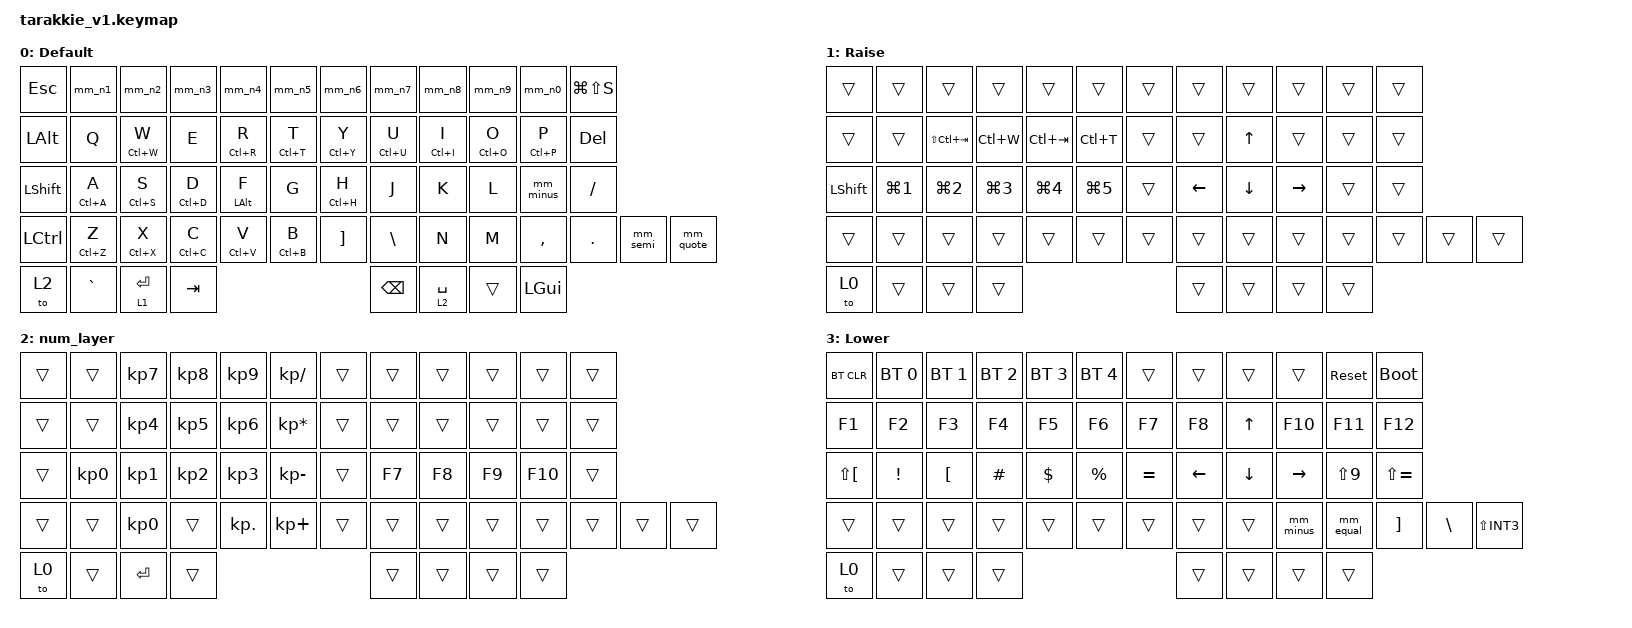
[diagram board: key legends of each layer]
/*
 * Copyright (c) 2025 The ZMK Contributors
 *
 * SPDX-License-Identifier: MIT
 */

#include <behaviors.dtsi>
#include <dt-bindings/zmk/bt.h>
#include <dt-bindings/zmk/keys.h>

// OS設定を日本語キーボードのまま使用するための変換定義

#define JP_DQUOTE       LS(N2)            // "
#define JP_AMPERSAND    LS(N6)            // &
#define JP_QUOTE        LS(N7)            // '
#define JP_EQUAL        LS(MINUS)         // =
#define JP_CARET        EQUAL             // ^
#define JP_YEN          INT3              // ¥
#define JP_PLUS         LS(SCLN)          // +
#define JP_TILDE        LS(EQUAL)         // ~
#define JP_PIPE         LS(INT3)          // |
#define JP_AT           LBKT              // @
#define JP_COLON        QUOT              // :
#define JP_ASTERISK     LS(QUOT)          // *
#define JP_BACKQUOTE    LS(LBKT)          // `
#define JP_UNDERSCORE   LS(INT1)          // _
#define JP_LBRACKET     RBKT              // [
#define JP_RBRACKET     BSLH              // ]
#define JP_LPAREN       LS(N8)            // (
#define JP_RPAREN       LS(N9)            // )
#define JP_LBRACE       LS(RBKT)          // {
#define JP_RBRACE       LS(BSLH)          // }

#define AS(keycode) &as LS(keycode) keycode

&mt {
    flavor = "tap-preferred";
};

/ {
    macros {
        tab_win: tab_win {
            compatible = "zmk,behavior-macro";
            #binding-cells = <0>;
            bindings = <&kp LG(TAB)>;
        };

        win_d: win_d {
            compatible = "zmk,behavior-macro";
            #binding-cells = <0>;
            bindings = <&kp LG(D)>;
        };

        l0_alt: l0_alt {
            compatible = "zmk,behavior-macro";
            #binding-cells = <0>;
            bindings =
                <&to 0>,
                <&macro_press>,
                <&kp LALT>,
                <&macro_pause_for_release>,
                <&macro_release>,
                <&kp LALT>;

            label = "L0_ALT";
        };

        l0_ctrl_a: l0_ctrl_a {
            compatible = "zmk,behavior-macro";
            #binding-cells = <0>;
            bindings = <&to 0 &kp LC(A)>;
            label = "L0_CTRL_A";
        };

        l0_ctrl_x: l0_ctrl_x {
            compatible = "zmk,behavior-macro";
            #binding-cells = <0>;
            bindings = <&to 0 &kp LC(X)>;
            label = "L0_CTRL_X";
        };

        l0_ctrl_c: l0_ctrl_c {
            compatible = "zmk,behavior-macro";
            #binding-cells = <0>;
            bindings = <&to 0 &kp LC(C)>;
            label = "L0_CTRL_C";
        };

        l0_ctrl_v: l0_ctrl_v {
            compatible = "zmk,behavior-macro";
            #binding-cells = <0>;
            bindings = <&to 0 &kp LC(V)>;
            label = "L0_CTRL_V";
        };
    };

    behaviors {
        ht_tab: ht_tab {
            compatible = "zmk,behavior-hold-tap";
            #binding-cells = <2>;
            flavor = "tap-preferred";
            tapping-term-ms = <200>;
            bindings = <&tab_win>, <&kp>;
        };

        ht_d: ht_d {
            compatible = "zmk,behavior-hold-tap";
            #binding-cells = <2>;
            flavor = "tap-preferred";
            tapping-term-ms = <200>;
            bindings = <&win_d>, <&kp>;
        };


        ht_g: ht_g {
            compatible = "zmk,behavior-hold-tap";
            #binding-cells = <2>;
            flavor = "tap-preferred";
            tapping-term-ms = <200>;
            bindings = <&to>, <&kp>;
        };

        ht_l0_alt: ht_l0_alt {
            compatible = "zmk,behavior-hold-tap";
            #binding-cells = <2>;
            flavor = "tap-preferred";
            tapping-term-ms = <200>;
            bindings = <&l0_alt>, <&kp>;
        };

        ht_l0_ctrl_a: ht_l0_ctrl_a {
            compatible = "zmk,behavior-hold-tap";
            #binding-cells = <2>;
            flavor = "tap-preferred";
            tapping-term-ms = <200>;
            bindings = <&l0_ctrl_a>, <&kp>;
        };

        ht_l0_ctrl_x: ht_l0_ctrl_x {
            compatible = "zmk,behavior-hold-tap";
            #binding-cells = <2>;
            flavor = "tap-preferred";
            tapping-term-ms = <200>;
            bindings = <&l0_ctrl_x>, <&kp>;
        };

        ht_l0_ctrl_c: ht_l0_ctrl_c {
            compatible = "zmk,behavior-hold-tap";
            #binding-cells = <2>;
            flavor = "tap-preferred";
            tapping-term-ms = <200>;
            bindings = <&l0_ctrl_c>, <&kp>;
        };

        ht_l0_ctrl_v: ht_l0_ctrl_v {
            compatible = "zmk,behavior-hold-tap";
            #binding-cells = <2>;
            flavor = "tap-preferred";
            tapping-term-ms = <200>;
            bindings = <&l0_ctrl_v>, <&kp>;
        };

        td_lang: td_lang {
            compatible = "zmk,behavior-tap-dance";
            #binding-cells = <0>;
            tapping-term-ms = <200>;
            bindings = <&kp LANGUAGE_1>, <&kp LANGUAGE_2>;
        };

        // US Keycap Emulation for JIS OS (Mod-Morph + Hold-Tap for Numbers)

        mm_n1: mm_n1 {
            compatible = "zmk,behavior-mod-morph";
            #binding-cells = <0>;
            bindings = <&mt F1 N1>, <&kp EXCLAMATION>;

            mods = <(MOD_LSFT|MOD_RSFT)>;
        };

        mm_n2: mm_n2 {
            compatible = "zmk,behavior-mod-morph";
            #binding-cells = <0>;
            bindings = <&mt F2 N2>, <&kp JP_AT>;

            mods = <(MOD_LSFT|MOD_RSFT)>;
        };

        mm_n3: mm_n3 {
            compatible = "zmk,behavior-mod-morph";
            #binding-cells = <0>;
            bindings = <&mt F3 N3>, <&kp HASH>;

            mods = <(MOD_LSFT|MOD_RSFT)>;
        };

        mm_n4: mm_n4 {
            compatible = "zmk,behavior-mod-morph";
            #binding-cells = <0>;
            bindings = <&mt F4 N4>, <&kp DOLLAR>;

            mods = <(MOD_LSFT|MOD_RSFT)>;
        };

        mm_n5: mm_n5 {
            compatible = "zmk,behavior-mod-morph";
            #binding-cells = <0>;
            bindings = <&mt F5 N5>, <&kp PERCENT>;

            mods = <(MOD_LSFT|MOD_RSFT)>;
        };

        mm_n6: mm_n6 {
            compatible = "zmk,behavior-mod-morph";
            #binding-cells = <0>;
            bindings = <&mt F6 N6>, <&kp JP_CARET>;

            mods = <(MOD_LSFT|MOD_RSFT)>;
        };

        mm_n7: mm_n7 {
            compatible = "zmk,behavior-mod-morph";
            #binding-cells = <0>;
            bindings = <&mt F7 N7>, <&kp JP_AMPERSAND>;

            mods = <(MOD_LSFT|MOD_RSFT)>;
        };

        mm_n8: mm_n8 {
            compatible = "zmk,behavior-mod-morph";
            #binding-cells = <0>;
            bindings = <&mt F8 N8>, <&kp JP_ASTERISK>;

            mods = <(MOD_LSFT|MOD_RSFT)>;
        };

        mm_n9: mm_n9 {
            compatible = "zmk,behavior-mod-morph";
            #binding-cells = <0>;
            bindings = <&mt F9 N9>, <&kp JP_LPAREN>;

            mods = <(MOD_LSFT|MOD_RSFT)>;
        };

        mm_n0: mm_n0 {
            compatible = "zmk,behavior-mod-morph";
            #binding-cells = <0>;
            bindings = <&mt F10 N0>, <&kp JP_RPAREN>;

            mods = <(MOD_LSFT|MOD_RSFT)>;
        };

        mm_semi: mm_semi {
            compatible = "zmk,behavior-mod-morph";
            #binding-cells = <0>;
            bindings = <&kp SEMI>, <&kp JP_COLON>;

            mods = <(MOD_LSFT|MOD_RSFT)>;
        };

        mm_quote: mm_quote {
            compatible = "zmk,behavior-mod-morph";
            #binding-cells = <0>;
            bindings = <&kp JP_QUOTE>, <&kp JP_DQUOTE>;

            mods = <(MOD_LSFT|MOD_RSFT)>;
        };

        mm_minus: mm_minus {
            compatible = "zmk,behavior-mod-morph";
            #binding-cells = <0>;
            bindings = <&kp MINUS>, <&kp JP_UNDERSCORE>;

            mods = <(MOD_LSFT|MOD_RSFT)>;
        };

        mm_equal: mm_equal {
            compatible = "zmk,behavior-mod-morph";
            #binding-cells = <0>;
            bindings = <&kp JP_EQUAL>, <&kp JP_PLUS>;

            mods = <(MOD_LSFT|MOD_RSFT)>;
        };
    };

    combos {
        compatible = "zmk,combos";

        win+d {
            bindings = <&kp LG(D)>;
            key-positions = <27 52>;
        };

        win+tab {
            bindings = <&kp LG(TAB)>;
            key-positions = <28 52>;
        };

        f2 {
            bindings = <&kp F2>;
            key-positions = <27 28>;
        };

        alt+f4 {
            bindings = <&kp LA(F4)>;
            key-positions = <27 28 52>;
        };

        lang1 {
            bindings = <&kp LANGUAGE_1>;
            key-positions = <28 31>;
        };

        lang2 {
            bindings = <&kp LANGUAGE_2>;
            key-positions = <27 32>;
        };

        paste {
            bindings = <&mt LG(V) LS(LC(V))>;
            key-positions = <52 40>;
        };

        combo_lparen {
            bindings = <&kp JP_LPAREN>;
            key-positions = <15 16>;
        };

        combo_rparen {
            bindings = <&kp JP_RPAREN>;
            key-positions = <19 20>;
        };
    };

    keymap {
        compatible = "zmk,keymap";

        default_layer {
            display-name = "Default";

            // ------------------------------------------------------------------------------------------------------------
            // |  ESC  |  1  |  2  |  3   |  4   |  5   |                   |  6   |  7    |  8    |  9   |   0   |   `   |
            // |  TAB  |  Q  |  W  |  E   |  R   |  T   |                   |  Y   |  U    |  I    |  O   |   P   |   -   |
            // |  CTRL |  A  |  S  | W+D  |  F   |  G   |                   |  H   |  J    |  K    |  L   |   ;   |   '   |
            // | SHIFT |  Z  |  X  |  C   |  V   |  B   |   "("  |  |  ")"  |  N   |  M    |  ,    |  .   |   ;   |   '   |
            //                     | ALT  | LANG | TAB |  ENTER |  | SPACE | BKSP  | BSPC  | GUI   |

            bindings = <
&kp ESC       &mm_n1         &mm_n2       &mm_n3       &mm_n4          &mm_n5       &mm_n6         &mm_n7         &mm_n8       &mm_n9       &mm_n0        &kp LG(LS(S))
&kp LEFT_ALT  &kp Q          &mt LC(W) W  &kp E        &mt LC(R) R     &mt LC(T) T  &mt LC(Y) Y    &mt LC(U) U    &mt LC(I) I  &mt LC(O) O  &mt LC(P) P   &kp DEL
&kp LSHIFT    &mt LC(A) A    &mt LC(S) S  &mt LC(D) D  &mt LEFT_ALT F  &kp G        &mt LC(H) H    &kp J          &kp K        &kp L        &mm_minus     &kp SLASH
&kp LCTRL     &mt LC(Z) Z    &mt LC(X) X  &mt LC(C) C  &mt LC(V) V     &mt LC(B) B  &kp JP_LBRACKET  &kp JP_RBRACKET  &kp N        &kp M        &kp COMMA     &kp DOT        &mm_semi  &mm_quote
&to 2         &kp GRAVE      &lt 1 ENTER  &kp TAB                                                  &kp BACKSPACE  &lt 2 SPACE  &trans       &kp LEFT_GUI
            >;
        };

        fn_layer {
            display-name = "Raise";
            bindings = <
&trans      &trans            &trans            &trans            &trans            &trans      &trans  &trans    &trans    &trans     &trans  &trans
&trans      &trans            &kp LS(LC(TAB))   &kp LC(W)         &kp LC(TAB)       &kp LC(T)   &trans  &trans    &kp UP    &trans     &trans  &trans
&kp LSHIFT  &kp LG(NUMBER_1)  &kp LG(NUMBER_2)  &kp LG(NUMBER_3)  &kp LG(NUMBER_4)  &kp LG(N5)  &trans  &kp LEFT  &kp DOWN  &kp RIGHT  &trans  &trans
&trans      &trans            &trans            &trans            &trans            &trans      &trans  &trans    &trans    &trans     &trans  &trans  &trans  &trans
&to 0       &trans            &trans            &trans                                                  &trans    &trans    &trans     &trans
            >;
        };

        num_layer {
            bindings = <
&trans  &trans           &kp KP_NUMBER_7  &kp KP_NUMBER_8  &kp KP_NUMBER_9  &kp KP_SLASH     &trans  &trans  &trans  &trans  &trans   &trans
&trans  &trans           &kp KP_NUMBER_4  &kp KP_NUMBER_5  &kp KP_NUMBER_6  &kp KP_MULTIPLY  &trans  &trans  &trans  &trans  &trans   &trans
&trans  &kp KP_NUMBER_0  &kp KP_NUMBER_1  &kp KP_NUMBER_2  &kp KP_NUMBER_3  &kp KP_MINUS     &trans  &kp F7  &kp F8  &kp F9  &kp F10  &trans
&trans  &trans           &kp KP_NUMBER_0  &trans           &kp KP_DOT       &kp KP_PLUS      &trans  &trans  &trans  &trans  &trans   &trans  &trans  &trans
&to 0   &trans           &kp ENTER        &trans                                                     &trans  &trans  &trans  &trans
            >;
        };

        setup_layer {
            display-name = "Lower";
            bindings = <
&bt BT_CLR        &bt BT_SEL 0  &bt BT_SEL 1  &bt BT_SEL 2  &bt BT_SEL 3  &bt BT_SEL 4  &trans        &trans    &trans    &trans     &sys_reset     &bootloader
&kp F1            &kp F2        &kp F3        &kp F4        &kp F5        &kp F6        &kp F7        &kp F8    &kp UP    &kp F10    &kp F11        &kp F12
&kp JP_BACKQUOTE  &kp EXCL      &kp JP_AT     &kp HASH      &kp DOLLAR    &kp PRCNT     &kp JP_CARET  &kp LEFT  &kp DOWN  &kp RIGHT  &kp JP_RPAREN  &kp JP_TILDE
&trans            &trans        &trans        &trans        &trans        &trans        &trans        &trans    &trans    &mm_minus  &mm_equal      &kp JP_LBRACKET  &kp JP_RBRACKET  &kp JP_PIPE
&to 0             &trans        &trans        &trans                                                  &trans    &trans    &trans     &trans
            >;
        };
    };
};
